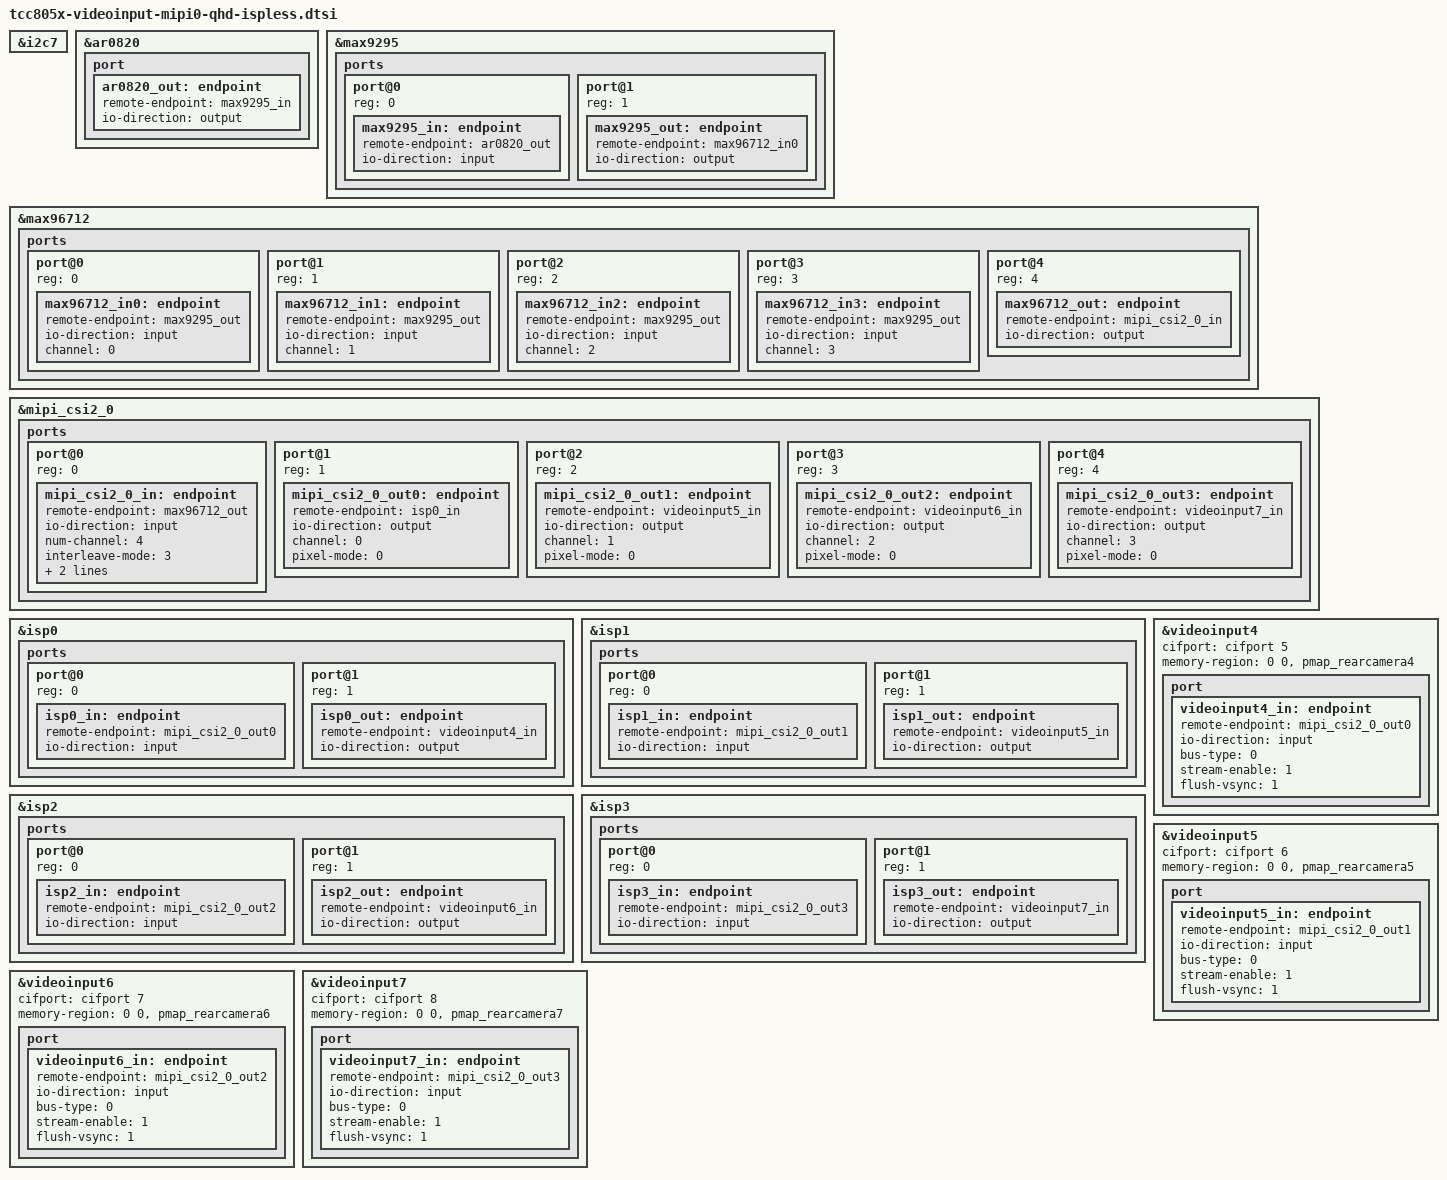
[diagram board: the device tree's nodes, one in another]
// SPDX-License-Identifier: (GPL-2.0-or-later OR MIT)
/*
 * Copyright (C) Telechips Inc.
 */

&i2c7 {
	status = "okay";
};

&ar0820 {
	/* Camera Image Sensor */
	status		= "okay";
	port {
		ar0820_out: endpoint {
			remote-endpoint = <&max9295_in>;
			io-direction	= "output";
		};
	};
};

&max9295 {
	/* serializer */
	status		= "okay";
	ports {
		#address-cells = <1>;
		#size-cells = <0>;
		port@0 {
			reg = <0>;
			max9295_in: endpoint {
				remote-endpoint = <&ar0820_out>;
				io-direction	= "input";
			};
		};
		port@1 {
			reg = <1>;
			max9295_out: endpoint {
				remote-endpoint = <&max96712_in0>;
				io-direction	= "output";
			};
		};
	};
};

&max96712 {
	/* deserializer */
	status		= "okay";
	ports {
		#address-cells = <1>;
		#size-cells = <0>;
		/*
		 * 0 ~ 3
		 * input ports. The number is matched with VC
		 *
		 * 4
		 * output port.
		 */
		port@0 {
			reg = <0>;
			max96712_in0: endpoint {
				remote-endpoint = <&max9295_out>;
				io-direction	= "input";
				channel		= <0>;
			};
		};
		port@1 {
			reg = <1>;
			max96712_in1: endpoint {
				remote-endpoint = <&max9295_out>;
				io-direction	= "input";
				channel		= <1>;
			};
		};
		port@2 {
			reg = <2>;
			max96712_in2: endpoint {
				remote-endpoint = <&max9295_out>;
				io-direction	= "input";
				channel		= <2>;
			};
		};
		port@3 {
			reg = <3>;
			max96712_in3: endpoint {
				remote-endpoint = <&max9295_out>;
				io-direction	= "input";
				channel		= <3>;
			};
		};
		port@4 {
			reg = <4>;
			max96712_out: endpoint {
				remote-endpoint = <&mipi_csi2_0_in>;
				io-direction	= "output";
			};
		};
	};
};

&mipi_csi2_0 {
	status = "okay";
	ports {
		#address-cells = <1>;
		#size-cells = <0>;
		/*
		 * 0
		 * input port.
		 *
		 * 1 ~ 4
		 * output ports. (1: VC0 ~ 4: VC3)
		 */
		port@0 {
			reg = <0>;
			mipi_csi2_0_in: endpoint {
				remote-endpoint	= <&max96712_out>;
				io-direction	= "input";
				num-channel = <4>;

				/*
				 * 0: CH0 only, no data interleave
				 * 1: DT only
				 * 2: VC only
				 * 3: VC and DT
				 */
				interleave-mode = <3>;
				hs-settle = <33>;
				data-lanes = <1 2 3 4>;
			};
		};
		port@1 {
			reg = <1>;
			mipi_csi2_0_out0: endpoint {
				remote-endpoint = <&isp0_in>;
				io-direction	= "output";
				channel		= <0>;
				/*
				 * 0: Single pixel mode
				 * 1: Dual pixel mode (RAW8/10/12, YUV422)
				 * 2: Quad pixel mode (RAW8/10/12)
				 * 3: Invalid
				 */
				pixel-mode = <0>;
			};
		};
		port@2 {
			reg = <2>;
			mipi_csi2_0_out1: endpoint {
				remote-endpoint	= <&videoinput5_in>;
				io-direction	= "output";
				channel		= <1>;
				pixel-mode = <0>;
			};
		};
		port@3 {
			reg = <3>;
			mipi_csi2_0_out2: endpoint {
				remote-endpoint	= <&videoinput6_in>;
				io-direction	= "output";
				channel		= <2>;
				pixel-mode = <0>;
			};
		};
		port@4 {
			reg = <4>;
			mipi_csi2_0_out3: endpoint {
				remote-endpoint	= <&videoinput7_in>;
				io-direction	= "output";
				channel		= <3>;
				pixel-mode = <0>;
			};
		};
	};
};

#if 0
/* only for TCC805X ES(TCS CV8050C-618) */
&isp_iommu0 {
	status = "okay";
};

&isp_iommu1 {
	status = "okay";
};

&isp_iommu2 {
	status = "okay";
};

&isp_iommu3 {
	status = "okay";
};
#endif

&isp0 {
	status = "okay";
#if 0
/* for isp mcu debugging */
	pinctrl-names = "default";
	pinctrl-0 = <&isp0_uart_tx &isp0_uart_rx>;
#endif

	ports {
		#address-cells = <1>;
		#size-cells = <0>;
		port@0 {
			reg = <0>;
			isp0_in: endpoint {
				remote-endpoint = <&mipi_csi2_0_out0>;
				io-direction	= "input";
			};
		};
		port@1 {
			reg = <1>;
			isp0_out: endpoint {
				remote-endpoint	= <&videoinput4_in>;
				io-direction	= "output";
			};
		};
	};
};

&isp1 {
	status = "okay";
#if 0
/* for isp mcu debugging */
	pinctrl-names = "default";
	pinctrl-0 = <&isp1_uart_tx &isp1_uart_rx>;
#endif

	ports {
		#address-cells = <1>;
		#size-cells = <0>;
		port@0 {
			reg = <0>;
			isp1_in: endpoint {
				remote-endpoint = <&mipi_csi2_0_out1>;
				io-direction	= "input";
			};
		};
		port@1 {
			reg = <1>;
			isp1_out: endpoint {
				remote-endpoint	= <&videoinput5_in>;
				io-direction	= "output";
			};
		};
	};
};

&isp2 {
	status = "okay";
#if 0
/* for isp mcu debugging */
	pinctrl-names = "default";
	pinctrl-0 = <&isp2_uart_tx &isp2_uart_rx>;
#endif

	ports {
		#address-cells = <1>;
		#size-cells = <0>;
		port@0 {
			reg = <0>;
			isp2_in: endpoint {
				remote-endpoint = <&mipi_csi2_0_out2>;
				io-direction	= "input";
			};
		};
		port@1 {
			reg = <1>;
			isp2_out: endpoint {
				remote-endpoint	= <&videoinput6_in>;
				io-direction	= "output";
			};
		};
	};
};

&isp3 {
	status = "okay";
#if 0
/* for isp mcu debugging */
	pinctrl-names = "default";
	pinctrl-0 = <&isp3_uart_tx &isp3_uart_rx>;
#endif

	ports {
		#address-cells = <1>;
		#size-cells = <0>;
		port@0 {
			reg = <0>;
			isp3_in: endpoint {
				remote-endpoint = <&mipi_csi2_0_out3>;
				io-direction	= "input";
			};
		};
		port@1 {
			reg = <1>;
			isp3_out: endpoint {
				remote-endpoint	= <&videoinput7_in>;
				io-direction	= "output";
			};
		};
	};
};

&videoinput4 {
	status		= "okay";
	cifport		= <&cifport		5>;
	memory-region	= <0 0 &pmap_rearcamera4>;
	port {
		videoinput4_in: endpoint {
			remote-endpoint	= <&mipi_csi2_0_out0>;
			io-direction	= "input";
			bus-type	= <0>;
			stream-enable	= <1>;	// VIN_CTRL.SE
			flush-vsync	= <1>;	// VIN_MISC.FVS
		};
	};
};

&videoinput5 {
	status		= "okay";
	cifport		= <&cifport		6>;
	memory-region	= <0 0 &pmap_rearcamera5>;
	port {
		videoinput5_in: endpoint {
			remote-endpoint	= <&mipi_csi2_0_out1>;
			io-direction	= "input";
			bus-type	= <0>;
			stream-enable	= <1>;	// VIN_CTRL.SE
			flush-vsync	= <1>;	// VIN_MISC.FVS
		};
	};
};

&videoinput6 {
	status		= "okay";
	cifport		= <&cifport		7>;
	memory-region	= <0 0 &pmap_rearcamera6>;
	port {
		videoinput6_in: endpoint {
			remote-endpoint	= <&mipi_csi2_0_out2>;
			io-direction	= "input";
			bus-type	= <0>;
			stream-enable	= <1>;	// VIN_CTRL.SE
			flush-vsync	= <1>;	// VIN_MISC.FVS
		};
	};
};

&videoinput7 {
	status		= "okay";
	cifport		= <&cifport		8>;
	memory-region	= <0 0 &pmap_rearcamera7>;
	port {
		videoinput7_in: endpoint {
			remote-endpoint	= <&mipi_csi2_0_out3>;
			io-direction	= "input";
			bus-type	= <0>;
			stream-enable	= <1>;	// VIN_CTRL.SE
			flush-vsync	= <1>;	// VIN_MISC.FVS
		};
	};
};
